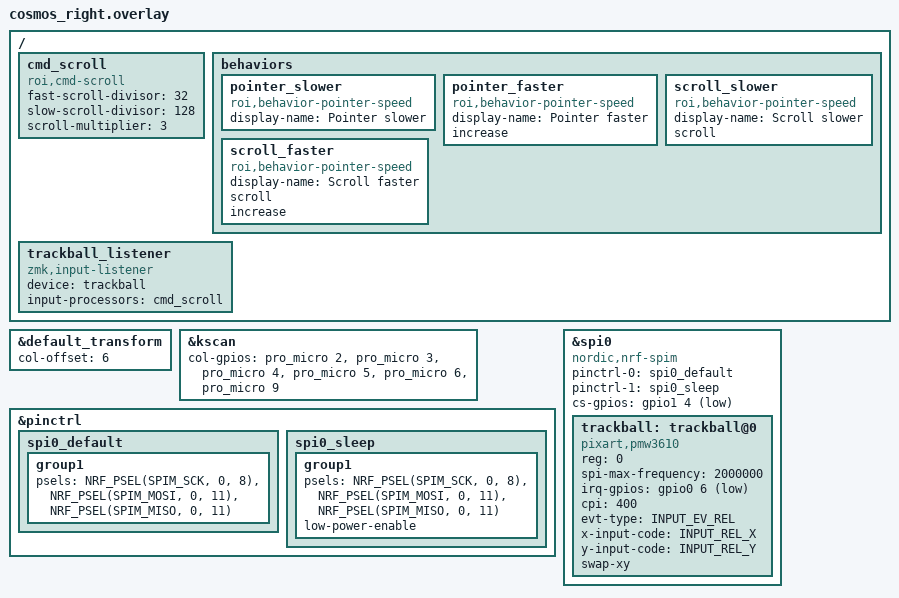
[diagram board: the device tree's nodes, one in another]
// Right columns — same new 017-edge pins as the left (C0 = outer pinky column).
// PMW3610 trackball (bottom of this file): SCLK 008, SDIO 011, NCS 104, MOTION 006.
// Exact module power: VDD -> VCC, GND -> GND; leave VDDIO/NRESET unconnected (sensor-wiring.html).
// Old mirrored GPIO assignments are retired for this rewire; key positions/transform are unchanged.

#include "cosmos.dtsi"

&default_transform {
    col-offset = <6>;
};

&kscan {
    col-gpios
        = <&pro_micro 2 GPIO_ACTIVE_HIGH> // C0 p Shift / ?, silk 017
        , <&pro_micro 3 GPIO_ACTIVE_HIGH> // C1 o l . (, silk 020
        , <&pro_micro 4 GPIO_ACTIVE_HIGH> // C2 i k , Alt, silk 022
        , <&pro_micro 5 GPIO_ACTIVE_HIGH> // C3 u j m Backspace, silk 024
        , <&pro_micro 6 GPIO_ACTIVE_HIGH> // C4 y h n Ctrl, silk 100
        , <&pro_micro 9 GPIO_ACTIVE_HIGH> // C5 unused, silk 106 (no wire)
        ;
};

#include <zephyr/dt-bindings/input/input-event-codes.h>

// SDIO is one shared data wire, so MOSI and MISO use the same pin (driver README).
&pinctrl {
    spi0_default: spi0_default {
        group1 {
            psels = <NRF_PSEL(SPIM_SCK, 0, 8)>,   // silk 008
                    <NRF_PSEL(SPIM_MOSI, 0, 11)>, // silk 011
                    <NRF_PSEL(SPIM_MISO, 0, 11)>;
        };
    };
    spi0_sleep: spi0_sleep {
        group1 {
            psels = <NRF_PSEL(SPIM_SCK, 0, 8)>,
                    <NRF_PSEL(SPIM_MOSI, 0, 11)>,
                    <NRF_PSEL(SPIM_MISO, 0, 11)>;
            low-power-enable;
        };
    };
};

&spi0 {
    status = "okay";
    compatible = "nordic,nrf-spim";
    pinctrl-0 = <&spi0_default>;
    pinctrl-1 = <&spi0_sleep>;
    pinctrl-names = "default", "sleep";
    cs-gpios = <&gpio1 4 GPIO_ACTIVE_LOW>; // NCS, silk 104

    trackball: trackball@0 {
        status = "okay";
        compatible = "pixart,pmw3610";
        reg = <0>;
        spi-max-frequency = <2000000>;
        irq-gpios = <&gpio0 6 (GPIO_ACTIVE_LOW | GPIO_PULL_UP)>; // MOTION, silk 006
        cpi = <400>;
        evt-type = <INPUT_EV_REL>;
        x-input-code = <INPUT_REL_X>;
        y-input-code = <INPUT_REL_Y>;
        // Correct mounted orientation: physical up previously moved left, and left moved up.
        swap-xy;
    };
};

/ {
    cmd_scroll: cmd_scroll {
        compatible = "roi,cmd-scroll";
        #input-processor-cells = <0>;
        // 400 CPI x 3/32 matches the earlier 600 CPI x 1/16 fast scroll rate.
        fast-scroll-divisor = <32>;
        slow-scroll-divisor = <128>;
        scroll-multiplier = <3>;
    };

    behaviors {
        pointer_slower: pointer_slower {
            compatible = "roi,behavior-pointer-speed";
            #binding-cells = <0>;
            display-name = "Pointer slower";
        };
        pointer_faster: pointer_faster {
            compatible = "roi,behavior-pointer-speed";
            #binding-cells = <0>;
            display-name = "Pointer faster";
            increase;
        };
        scroll_slower: scroll_slower {
            compatible = "roi,behavior-pointer-speed";
            #binding-cells = <0>;
            display-name = "Scroll slower";
            scroll;
        };
        scroll_faster: scroll_faster {
            compatible = "roi,behavior-pointer-speed";
            #binding-cells = <0>;
            display-name = "Scroll faster";
            scroll;
            increase;
        };
    };

    trackball_listener {
        compatible = "zmk,input-listener";
        device = <&trackball>;
        input-processors = <&cmd_scroll>;
    };
};
